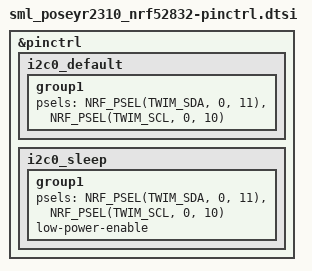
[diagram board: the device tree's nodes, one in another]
&pinctrl {
	i2c0_default: i2c0_default {
		group1 {
			psels = <NRF_PSEL(TWIM_SDA, 0, 11)>,
					<NRF_PSEL(TWIM_SCL, 0, 10)>;
		};
	};

	i2c0_sleep: i2c0_sleep {
		group1 {
			psels = <NRF_PSEL(TWIM_SDA, 0, 11)>,
					<NRF_PSEL(TWIM_SCL, 0, 10)>;
			low-power-enable;
		};
	};
};
